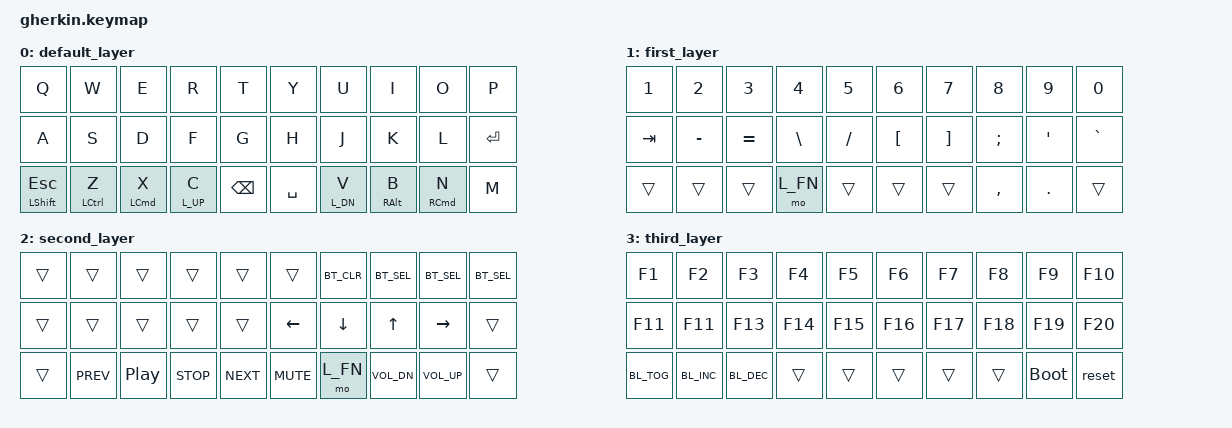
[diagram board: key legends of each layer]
/*
 * Copyright (c) 2020 The ZMK Contributors
 *
 * SPDX-License-Identifier: MIT
 */

#include <behaviors.dtsi>
#include <dt-bindings/zmk/keys.h>
#include <dt-bindings/zmk/bt.h>

#define L_AL 0
#define L_UP 1
#define L_DN 2
#define L_FN 3

/ {
    keymap {
        compatible = "zmk,keymap";

        // L_AL
        default_layer {
            // --------------------------------------------------------------------------------------
            // | Q         | W      | E     | R    | T      | Y     | U      | I     | O     | P    |
            // | A         | S      | D     | F    | G      | H     | J      | K     | L     | RET  |
            // | Shift/ESC | Ctrl/Z | Cmd/X | Up/C | Backsp | Space | Down/V | Opt/B | Cmd/N | M    |
            // --------------------------------------------------------------------------------------
            bindings = 
                <&kp Q          &kp W       &kp E       &kp R       &kp T       &kp Y       &kp U       &kp I           &kp O       &kp P
                 &kp A          &kp S       &kp D       &kp F       &kp G       &kp H       &kp J       &kp K           &kp L       &kp RET
                 &mt LSHFT ESC  &mt LCTRL Z &mt LCMD X  &lt L_UP C  &kp BSPC    &kp SPACE   &lt L_DN V  &mt RALT B      &mt RCMD N  &kp M
                 >;
        };

        // L_UP
        first_layer {
            // -------------------------------------------------------------
            // | 1/! | 2/@ | 3/# | 4/$ | 5/% | 6/^ | 7/& | 8/* | 9/( | 0/) |
            // | Tab | -/_ | =/+ | \/| | //? | [/} | ]/} | ;/: | '/" | `/~ |
            // |     |     |     |     | FN  |     |     | ,/< | .\> |     |
            // -------------------------------------------------------------
            bindings = 
                <&kp N1         &kp N2      &kp N3      &kp N4      &kp N5      &kp N6      &kp N7      &kp N8          &kp N9          &kp N0
                 &kp TAB        &kp MINUS   &kp EQUAL   &kp BSLH    &kp FSLH    &kp LBKT    &kp RBKT    &kp SEMI        &kp SQT         &kp GRAVE
                 &trans         &trans      &trans      &mo L_FN    &trans      &trans      &trans      &kp COMMA       &kp DOT         &trans
                 >;
        };

        // L_DN
        second_layer {
            // ----------------------------------------------------------------------------------
            // | M1    | MUp   | M2      | MWUp   |      |      | CLR  | BL 2    | BL 1  | BL 0 |
            // | MLeft | MDown | MRight  | MWDown |      | Left | Down | Up      | Right |      |
            // |       | Prev  | PlyPaus | Stop   | Next | Mute | FN   | VolDown | VolUp |      |
            // ----------------------------------------------------------------------------------
            // TODO: Add mouse keys when they're available
            bindings =
                <&trans         &trans      &trans      &trans      &trans      &trans      &kp BT_CLR  &kp BT_SEL 2    &kp BT_SEL 1    &kp BT_SEL 0
                 &trans         &trans      &trans      &trans      &trans      &kp LEFT    &kp DOWN    &kp UP          &kp RIGHT       &trans
                 &trans         &kp C_PREV  &kp C_PP    &kp C_STOP  &kp C_NEXT  &kp C_MUTE  &mo L_FN    &kp C_VOL_DN    &kp C_VOL_UP    &trans
                 >;
        };

        // L_FN
        third_layer {
            // -------------------------------------------------------------
            // | F1  | F2  | F3  | F4  | F5  | F6  | F7  | F8  | F9  | F10 |
            // | F10 | F12 | F13 | F14 | F15 | F16 | F17 | F18 | F19 | F20 |
            // | TOG | INC | DEC |     |     |     |     |     | BL  | RST |
            // -------------------------------------------------------------
            bindings =
                <&kp F1         &kp F2      &kp F3      &kp F4      &kp F5      &kp F6      &kp F7      &kp F8          &kp F9          &kp F10
                 &kp F11        &kp F11     &kp F13     &kp F14     &kp F15     &kp F16     &kp F17     &kp F18         &kp F19         &kp F20
                 &kp BL_TOG     &kp BL_INC  &kp BL_DEC  &trans      &trans      &trans      &trans      &trans          &bootloader     &reset
                 >;
        };
    };
};
